# ATUC128D4 device description
Architecture: AVR32_UC3; Family: AVR UC3
Registers are 32-bit, read-write, reset 0x0 unless marked. A register's access mark holds for its fields unless they carry their own. Offsets are from the block's base; [hi:lo] are bit positions; {n}, {i} and the like mark numbered series; 'fields as' and 'values as' point back to an identical list.

## INTC — Interrupt Controller
Instances: INTC 0xFFFF1000
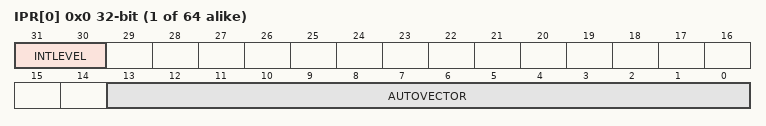
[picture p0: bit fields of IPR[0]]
{0x0+4i} IPR[{i}] (i=0..63) — Interrupt Priority Register
  [31:30] INTLEVEL — Interrupt Level
    {v}=INT{v} (v=0..3)
  [13:0] AUTOVECTOR — Handler offset
{0x100+4i} IRR[{i}] (i=0..63) ro — Interrupt Request Register
{0x200+4i} ICR[{i}] (i=0..3) ro — Interrupt Cause Register
  [5:0] CAUSE — Cause Group Number

## ADCIFD — ADC controller interface
Instances: ADCIFD 0xffff5400
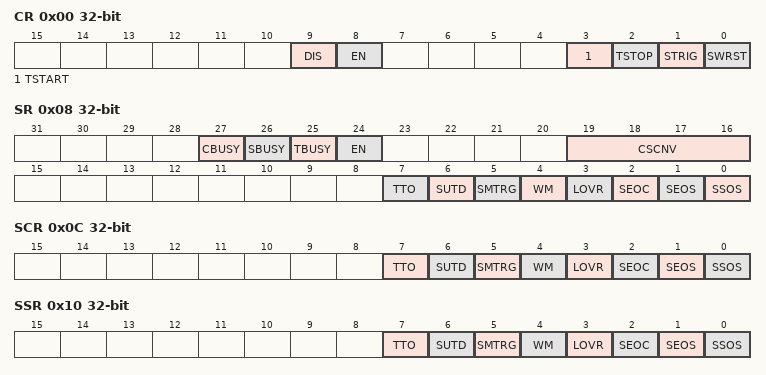
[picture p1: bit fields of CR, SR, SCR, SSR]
0x00 CR wo
  [9] DIS — ADCIFD disable
  [8] EN — ADCIFD enable
  [3] TSTART — Internal timer start bit
  [2] TSTOP — Internal timer stop bit
  [1] STRIG — Sequencer trigger
  [0] SWRST — Software reset
0x04 CFG
  [0] PRM — Power reduction mode
0x08 SR ro
  [27] CBUSY — Conversion busy
  [26] SBUSY — Sequencer busy
  [25] TBUSY — Timer busy
  [24] EN — Enable
  [19:16] CSCNV — Current sequencer conversion
  [7] TTO — Timer time-out
  [6] SUTD — Start-up time done
  [5] SMTRG — Sequencer missed trigger event
  [4] WM — Window monitor
  [3] LOVR — Sequencer last converted value overrun
  [2] SEOC — Sequencer end of conversion
  [1] SEOS — Sequencer end of sequence
  [0] SSOS — Sequencer start of sequence
0x0C SCR wo
  [7] TTO — Timer time-out
  [6] SUTD — Start-up time done
  [5] SMTRG — Sequencer missed trigger event
  [4] WM — Window monitor
  [3] LOVR — Sequencer last converted value overrun
  [2] SEOC — Sequencer end of conversion
  [1] SEOS — Sequencer end of sequence
  [0] SSOS — Sequencer start of sequence
0x10 SSR wo
  fields as SCR
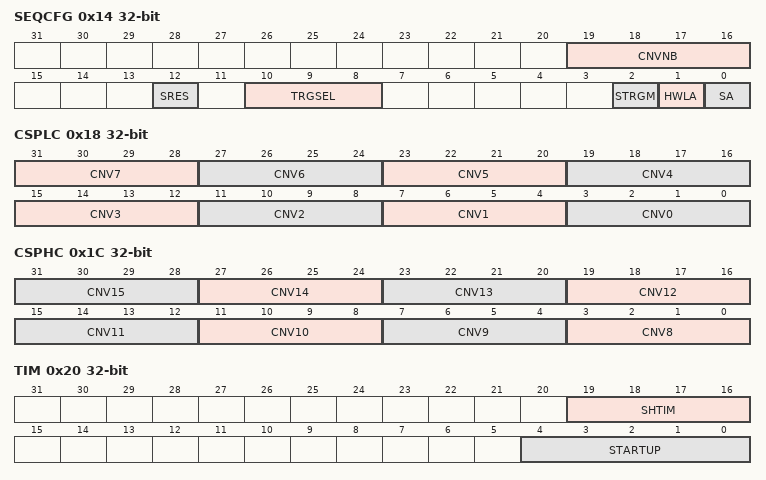
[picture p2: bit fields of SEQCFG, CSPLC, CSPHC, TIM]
0x14 SEQCFG
  [19:16] CNVNB — Number of conversions in a sequence
  [12] SRES — Resolution
  [10:8] TRGSEL — Trigger selection
  [2] STRGM — Sequencer trigger mode
  [1] HWLA — Half word left adjust
  [0] SA — Software acknowledge
0x18 CSPLC
  [4n+3:4n] CNV{n} (n=3..7) — Multiplexer selection for the {n+1}th conversion
  [11:8] CNV2 — Multiplexer selection for the 3rd conversion
  [7:4] CNV1 — Multiplexer selection for the 2nd conversion
  [3:0] CNV0 — Multiplexer selection for the 1st conversion
0x1C CSPHC
  [4n-29:4n-32] CNV{n} (n=8..15) — Multiplexer selection for the {n}th conversion
0x20 TIM
  [19:16] SHTIM — Sample and hold time
  [4:0] STARTUP — Startup time
0x24 ITIMER
  [15:0] ITMC — Internal timer max counter
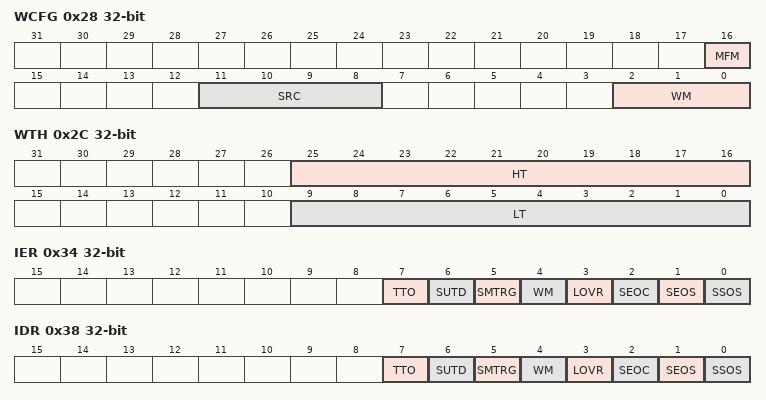
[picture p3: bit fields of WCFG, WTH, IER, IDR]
0x28 WCFG
  [16] MFM — Monitor filter mode
  [11:8] SRC — Source selection
  [2:0] WM — Window mode
0x2C WTH
  [25:16] HT — High threshold
  [9:0] LT — Low threshold
0x30 LCV ro
  [15:0] LCV — Last converted value
0x34 IER wo
  fields as SCR
0x38 IDR wo
  fields as SCR
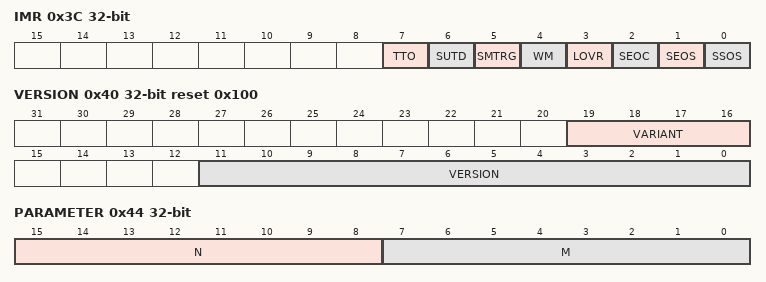
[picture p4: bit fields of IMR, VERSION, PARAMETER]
0x3C IMR ro
  fields as SCR
0x40 VERSION ro reset 0x100
  [19:16] VARIANT — Variant number
  [11:0] VERSION — Version number
0x44 PARAMETER ro reset not defined
  [15:8] N — Number of channels
  [7:0] M — Number of sequencer states

## AST — Asynchronous Timer
Instances: AST 0xffff1800
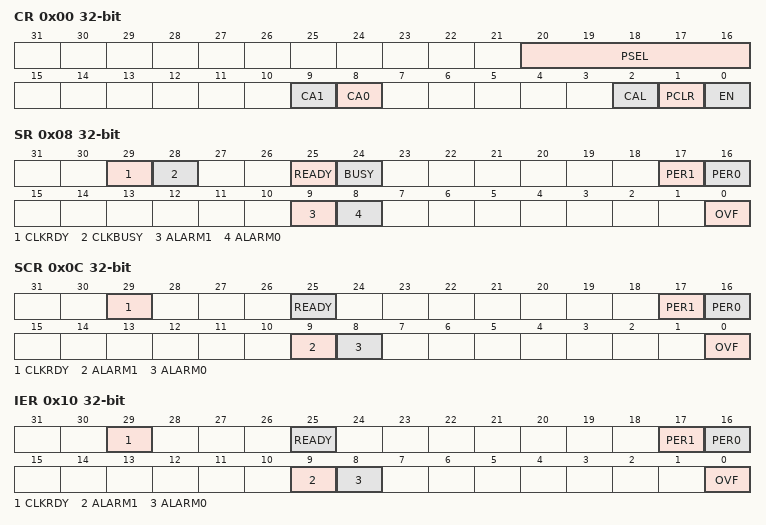
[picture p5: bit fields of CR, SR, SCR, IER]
0x00 CR — Control Register
  [20:16] PSEL — Prescaler Select
  [9] CA1 — Clear on Alarm
  [8] CA0 — Clear on Alarm
  [2] CAL — Calendar mode
  [1] PCLR — Prescaler Clear
  [0] EN — Enable
0x04 CV — Counter Value
  [31:0] VALUE — AST Value
0x08 SR ro — Status Register
  [29] CLKRDY — Clock Ready
  [28] CLKBUSY — Clock Busy
  [25] READY — AST Ready
  [24] BUSY — AST Busy
  [17] PER1 — Periodic 1
  [16] PER0 — Periodic 0
  [9] ALARM1
  [8] ALARM0
  [0] OVF — Overflow
0x0C SCR wo — Status Clear Register
  [29] CLKRDY — Clock Ready
  [25] READY — AST Ready
  [17] PER1 — Periodic 1
  [16] PER0 — Periodic 0
  [9] ALARM1
  [8] ALARM0
  [0] OVF — Overflow
0x10 IER wo — Interrupt Enable Register
  fields as SCR
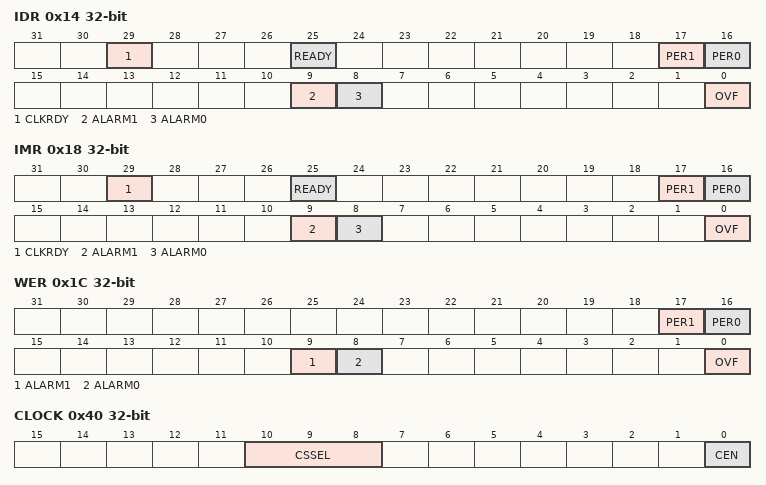
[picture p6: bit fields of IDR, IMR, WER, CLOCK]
0x14 IDR wo — Interrupt Disable Register
  fields as SCR
0x18 IMR ro — Interrupt Mask Register
  fields as SCR
0x1C WER — Wake Enable Register
  [17] PER1 — Periodic 1
  [16] PER0 — Periodic 0
  [9] ALARM1
  [8] ALARM0
  [0] OVF — Overflow
0x20 AR0 — Alarm Register 0
  [31:0] VALUE — Alarm Value
0x24 AR1 — Alarm Register 1
  [31:0] VALUE — Alarm Value
0x30 PIR0 — Periodic Interval Register 0
  [4:0] INSEL — Interval Select
0x34 PIR1 — Periodic Interval Register 1
  [4:0] INSEL — Interval Select
0x40 CLOCK — Clock Control Register
  [10:8] CSSEL — Clock Source Selection
    0=SLOWCLOCK; 1=32KHZCLK; 2=PBCLOCK; 3=GCLK; 4=1KHZCLK
  [0] CEN — Clock Enable
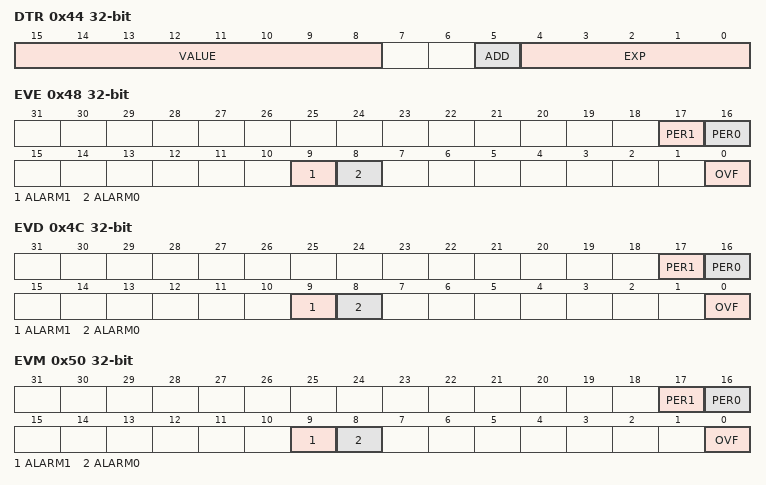
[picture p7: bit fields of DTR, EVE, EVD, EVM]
0x44 DTR — Digital Tuner Register
  [15:8] VALUE, [5] ADD, [4:0] EXP
0x48 EVE wo — Event Enable Register
  [17] PER1 — Periodic 1
  [16] PER0 — Perioidc 0
  [9] ALARM1
  [8] ALARM0
  [0] OVF — Overflow
0x4C EVD wo — Event Disable Register
  fields as EVE
0x50 EVM ro — Event Mask Register
  fields as EVE
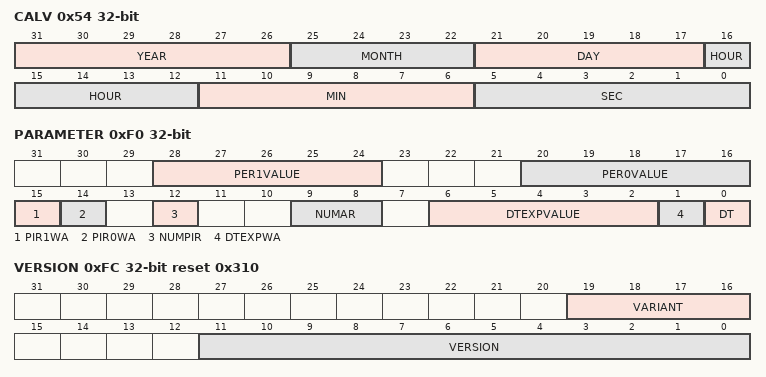
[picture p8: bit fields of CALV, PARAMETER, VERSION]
0x54 CALV — Calendar Value
  [31:26] YEAR
  [25:22] MONTH
  [21:17] DAY
  [16:12] HOUR
  [11:6] MIN — Minute
  [5:0] SEC — Second
0xF0 PARAMETER ro reset not defined
  [28:24] PER1VALUE — Periodic Interval 1 Value
  [20:16] PER0VALUE — Periodic Interval 0 Value
  [15] PIR1WA — Periodic Interval 1 Writeable
  [14] PIR0WA — Periodic Interval 0 Writeable
  [12] NUMPIR — Number of periodic comparators
    0=ONE; 1=TWO
  [9:8] NUMAR — Number of alarm comparators
    0=ZERO; 1=ONE; 2=TWO
  [6:2] DTEXPVALUE — Digital Tuner Exponent Value
  [1] DTEXPWA — Digital Tuner Exponent Writeable
  [0] DT — Digital Tuner
    0=OFF; 1=ON
0xFC VERSION ro reset 0x310
  [19:16] VARIANT — Variant Number
  [11:0] VERSION — Version Number
